# MCSPI0_CFG register map
Vendor: Texas Instruments
Peripheral module from a debugger description file (folder am65x).
Registers are 32-bit, access per field, reset 0x0 unless marked. A register's access mark holds for its fields unless they carry their own. Offsets are as the file gives them; lines under a group give offsets from that group; [hi:lo] are bit positions; {n}, {i} and the like mark numbered series; 'fields as' and 'values as' point back to an identical list; <NAME> marks a mode.

## MCSPI0_CFG
0x00 MCSPI_HL_REV ro reset 0x40301A0B — IP Revision Identifier (X.Y.R) Used by software to track features, bugs, and compatibility
  [31:0] REVISION — IP Revision
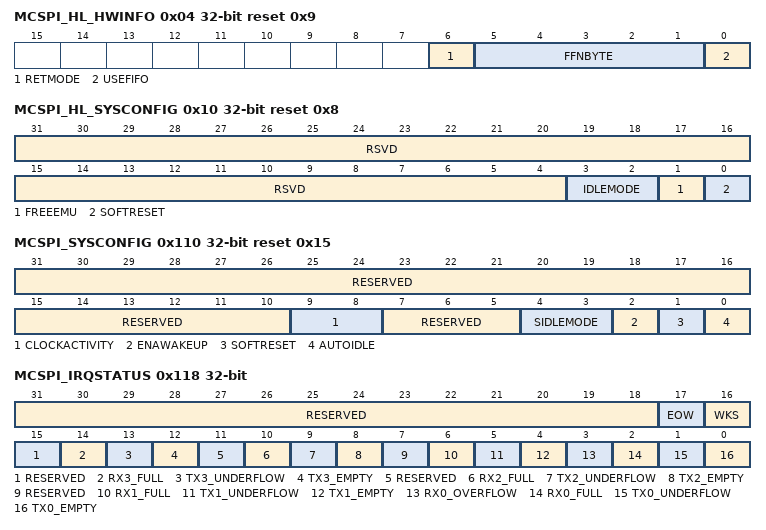
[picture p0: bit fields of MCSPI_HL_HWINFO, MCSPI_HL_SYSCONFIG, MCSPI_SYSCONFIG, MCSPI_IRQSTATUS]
0x04 MCSPI_HL_HWINFO ro reset 0x9 — Information about the IP module's hardware configuration, that is, typically the module's HDL generics (if any). Actual field format and encoding is up to the module's designer to decide. Some of the MCSPI features described in this section may not be supported on this family of devices. For more information, see , MCSPI Not Supported Features.
  [6] RETMODE — Retention Mode generic parameter. This bit field indicates whether the retention mode is supported using the pin PIRFFRET.
  [5:1] FFNBYTE — FIFO number of byte generic parameter 1h (R) = FIFO 16 bytes depth 2h (R) = FIFO 32 bytes depth 4h (R) = FIFO 64 bytes depth 8h (R) = FIFO 128 bytes depth 10h (R) = FIFO 256 bytes depth
  [0] USEFIFO — Use of a FIFO enable: 0h (R) = FIFO not implemented in design 1h (R) = FIFO and its management implemented in design with depth defined by FFNBYTE generic
0x10 MCSPI_HL_SYSCONFIG reset 0x8 — Clock management configuration Some of the MCSPI features described in this section may not be supported on this family of devices. For more information, see , MCSPI Not Supported Features.
  [31:4] RSVD ro — Reads returns 0
  [3:2] IDLEMODE rw — Configuration of the local target state management mode. 0h (R/W) = Force-idle mode: local target's IDLE state follows (acknowledges) the system's clock stop requests unconditionally, that is, regardless of the IP module's internal requirements. Backup mode, for debug only. 1h (R/W) = No-idle mode: local target never enters IDLE state. Backup mode, for debug only. 2h (R/W) = Smart-idle mode: local target's IDLE state eventually follows (acknowledges) the system's clock stop requests, depending on the IP module's internal requirements. IP module shall not generate (IRQ- or DMA-request-related) wake-up events. 3h (R/W) = Smart-idle wake-up-capable mode: local target's IDLE state eventually follows (acknowledges) the system's clock stop requests, depending on the IP module's internal requirements. IP module may generate (IRQ- or DMA-request-related) wake-up events when in IDLE state.
  [1] FREEEMU rw — Sensitivity to emulation (debug) suspend input signal. 0h (R/W) = IP module is sensitive to emulation suspend. 1h (R/W) = IP module is not sensitive to emulation suspend.
  [0] SOFTRESET rw — Software reset. (Optional) 0h (R/W) = Reset done, no pending action 1h (R/W) = Initiate software reset
0x100 MCSPI_REVISION ro reset 0x2B — This register contains the revision number.
  [31:0] REVISION — IP revision
0x110 MCSPI_SYSCONFIG reset 0x15 — This register allows controlling various parameters of the configuration interface and is not affected by software reset. Some of the MCSPI features described in this section may not be supported on this family of devices. For more information, see , MCSPI Not Supported Features.
  [31:10] RESERVED ro — Reads returns 0
  [9:8] CLOCKACTIVITY rw — Clocks activity during wake-up mode period 0h (R/W) = Interface and functional clocks may be switched off. 1h (R/W) = Interface clock is maintained. Functional clock may be switched off. 2h (R/W) = Functional clock is maintained. Interface clock may be switched off. 3h (R/W) = Interface and functional clocks are maintained.
  [7:5] RESERVED ro — Reads returns 0
  [4:3] SIDLEMODE rw — Power management 0h (R/W) = If an IDLE request is detected, the MCSPI acknowledges it unconditionally and goes in inactive mode. Interrupt, DMA requests and wake-up lines are unconditionally deasserted and the module wake-up capability is deactivated even if the 1h (R/W) = If an IDLE request is detected, the request is ignored and the module does not switch to wake-up mode, and keeps on behaving normally. 2h (R/W) = If an IDLE request is detected, the module will switch to wake-up mode based on its internal activity, and the wake-up capability can be used if the bit 3h (R/W) = Reserved - do not use.
  [2] ENAWAKEUP rw — Wake-up feature control 0h (R/W) = Wake-up capability is disabled. 1h (R/W) = Wake-up capability is enabled.
  [1] SOFTRESET rw — Software reset. During reads it always returns 0. 0h (R/W) = (write) Normal mode 1h (R/W) = (write) Set this bit to 1 to trigger a module reset. The bit is automatically reset by the hardware.
  [0] AUTOIDLE rw — Internal interface clock-gating strategy 0h (R/W) = Interface clock is free-running. 1h (R/W) = Automatic interface clock gating strategy is applied, based on the configuration interface activity.
0x114 MCSPI_SYSSTATUS ro reset 0x1 — This register provides status information about the module excluding the interrupt status information.
  [0] RESETDONE — Internal reset monitoring 0h (R) = Internal module reset is ongoing 1h (R) = Reset completed
0x118 MCSPI_IRQSTATUS access not given — The interrupt status regroups all the status of the module internal events that can generate an interrupt. Some of the MCSPI features described in this section may not be supported on this family of devices. For more information, see , MCSPI Not Supported Features.
  [31:18] RESERVED ro — Reads returns 0
  [17] EOW — End of word count event when a channel is enabled using the FIFO buffer and the channel had sent the number of MCSPI word defined by 0h (R/W) = Event false 1h (R/W) = Event status bit is reset (access RW1C)
  [16] WKS — Wake-up event in slave mode when an active control signal is detected on the SPIEN line programmed in the field 0h (R/W) = Event status bit unchanged 1h (R/W) = Event is pending (access RW1C)
  [15] RESERVED ro — Reads returns 0
  [14] RX3_FULL — Receiver register is full or almost full. Only when Channel 3 is enabled 0h (R/W) = Event status bit unchanged 1h (R/W) = Event is pending (access RW1C)
  [13] TX3_UNDERFLOW — Transmitter register underflow. Only when Channel 3 is enabled. 0h (R/W) = Event status bit unchanged 1h (R/W) = Event is pending (access RW1C)
  [12] TX3_EMPTY — Transmitter register is empty or almost empty. 0h (R/W) = Event status bit unchanged 1h (R/W) = Event is pending (access RW1C)
  [11] RESERVED ro — Reads returns 0.
  [10] RX2_FULL — Receiver register full or almost full. Channel 2 0h (R/W) = Event status bit unchanged 1h (R/W) = Event is pending (access RW1C)
  [9] TX2_UNDERFLOW — Transmitter register underflow. Channel 2 0h (R/W) = Event status bit unchanged 1h (R/W) = Event is pending (access RW1C)
  [8] TX2_EMPTY — Transmitter register empty or almost empty. Channel 2 0h (R/W) = Event status bit unchanged 1h (R/W) = Event is pending (access RW1C)
  [7] RESERVED ro — Reads returns 0
  [6] RX1_FULL — Receiver register full or almost full. Channel 1 0h (R/W) = Event status bit unchanged 1h (R/W) = Event is pending (access RW1C)
  [5] TX1_UNDERFLOW — Transmitter register underflow. Channel 1 0h (R/W) = Event status bit unchanged 1h (R/W) = Event is pending (access RW1C)
  [4] TX1_EMPTY — Transmitter register empty or almost empty. Channel 1 0h (R/W) = Event status bit unchanged 1h (R/W) = Event is pending (access RW1C)
  [3] RX0_OVERFLOW — Receiver register overflow (slave mode only). Channel 0 0h (R/W) = Event status bit unchanged 1h (R/W) = Event is pending (access RW1C)
  [2] RX0_FULL — Receiver register full or almost full. Channel 0 0h (R/W) = Event status bit unchanged 1h (R/W) = Event is pending (access RW1C)
  [1] TX0_UNDERFLOW — Transmitter register underflow. Channel 0 0h (R/W) = Event status bit unchanged 1h (R/W) = Event is pending (access RW1C)
  [0] TX0_EMPTY — Transmitter register empty or almost empty. Channel 0 0h (R/W) = Event status bit unchanged 1h (R/W) = Event is pending (access RW1C)
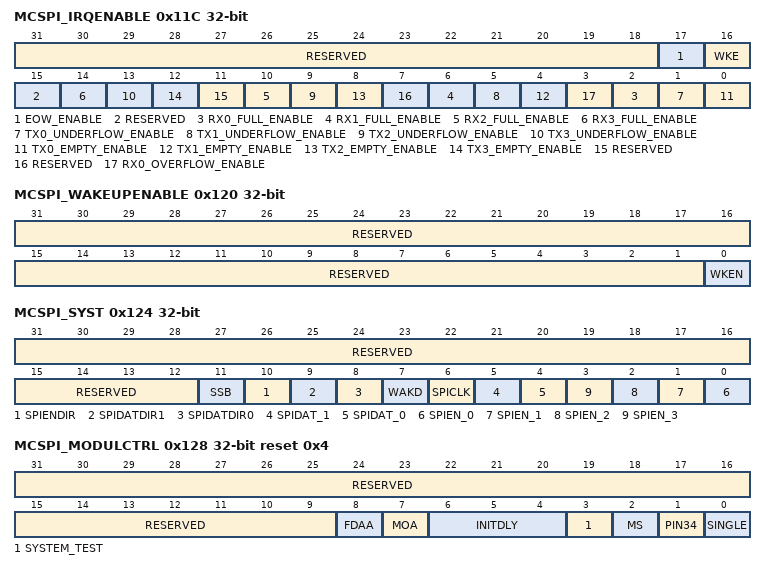
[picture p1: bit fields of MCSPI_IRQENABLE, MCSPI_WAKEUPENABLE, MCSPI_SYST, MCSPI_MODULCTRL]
0x11C MCSPI_IRQENABLE — This register allows enabling/disabling of the module internal sources of interrupt, on an event-by-event basis. Some of the MCSPI features described in this section may not be supported on this family of devices. For more information, see , MCSPI Not Supported Features.
  [31:18] RESERVED ro — Reads return 0.
  [17] EOW_ENABLE rw — End of Word count Interrupt Enable. 0h (R/W) = Interrupt disabled 1h (R/W) = Interrupt enabled
  [16] WKE rw — Wake-up event interrupt enable in slave mode when an active control signal is detected on the SPIEN line programmed in the 0h (R/W) = Interrupt disabled 1h (R/W) = Interrupt enabled
  [15] RESERVED ro — Reads returns 0.
  [4n+2] RX{n}_FULL_ENABLE rw (n=0..3) — Receiver register Full Interrupt Enable. Channel {n} 0h (R/W) = Interrupt disabled 1h (R/W) = Interrupt enabled
  [4n+1] TX{n}_UNDERFLOW_ENABLE rw (n=0..3) — Transmitter register Underflow Interrupt Enable. Channel {n} 0h (R/W) = Interrupt disabled 1h (R/W) = Interrupt enabled
  [4n] TX{n}_EMPTY_ENABLE rw (n=0..3) — Transmitter register Empty Interrupt Enable. Channel {n} 0h (R/W) = Interrupt disabled 1h (R/W) = Interrupt enabled
  [11] RESERVED ro — Reads return 0.
  [7] RESERVED ro — Reads return 0.
  [3] RX0_OVERFLOW_ENABLE rw — Receiver register Overflow Interrupt Enable. Channel 0 0h (R/W) = Interrupt disabled 1h (R/W) = Interrupt enabled
0x120 MCSPI_WAKEUPENABLE — The wake-up enable register allows enabling and disabling of the module internal sources of wakeup on event-by-event basis. Some of the MCSPI features described in this section may not be supported on this family of devices. For more information, see , MCSPI Not Supported Features.
  [31:1] RESERVED ro — Reads returns 0.
  [0] WKEN rw — Wake-up functionality in slave mode when an active control signal is detected on the SPIEN line programmed in the 0h (R/W) = The event is not allowed to wake-up the system, even if the global control bit 1h (R/W) = The event is allowed to wake-up the system if the global control bit
0x124 MCSPI_SYST — This register is used to check the correctness of the system interconnect either internally to peripheral bus, or externally to device I/O pads, when the module is configured in system test (SYSTEST) mode.
  [31:12] RESERVED ro — Reads returns 0.
  [11] SSB rw — Set status bit 0h (R/W) = No action. Writing 0 does not clear already set status bits. This bit must be cleared before trying to clear a status bit of the 1h (R/W) = Force to 1 all status bits of
  [10] SPIENDIR rw — Set the direction of the SPIEN[3:0] lines and SPICLK line. 0h (R/W) = Output (as in master mode) 1h (R/W) = Input (as in slave mode)
  [9] SPIDATDIR1 rw — Set the direction of the SPIDAT[1]. 0h (R/W) = Output 1h (R/W) = Input
  [8] SPIDATDIR0 rw — Set the direction of the SPIDAT[0]. 0h (R/W) = Output 1h (R/W) = Input
  [7] WAKD rw — SWAKEUP output (signal data value of internal signal to system). 0h (R/W) = The pin is driven low. 1h (R/W) = The pin is driven high.
  [6] SPICLK rw — SPICLK line (signal data value)
  [5] SPIDAT_1 rw — SPIDAT[1] line (signal data value)
  [4] SPIDAT_0 rw — SPIDAT[0] line (signal data value)
  [n] SPIEN_{n} rw (n=0..3) — SPIEN[{n}] line (signal data value)
0x128 MCSPI_MODULCTRL reset 0x4 — This register is dedicated to the configuration of the serial peripheral interface.
  [31:9] RESERVED ro — Reads returns 0.
  [8] FDAA rw — FIFO DMA address 256-bit aligned 0h (R/W) = FIFO data managed by MCSPI_TX(i) and MCSPI_RX(i) registers. 1h (R/W) = FIFO data managed by
  [7] MOA rw — Multiple word configuration interface access: 0h (R/W) = Multiple word access disabled 1h (R/W) = Multiple word access enabled with FIFO
  [6:4] INITDLY rw — Initial MCSPI delay for first transfer: 0h (R/W) = No delay for first MCSPI transfer. 1h (R/W) = The controller wait 4 MCSPI bus clock 2h (R/W) = The controller wait 8 MCSPI bus clock 3h (R/W) = The controller wait 16 MCSPI bus clock 4h (R/W) = The controller wait 32 MCSPI bus clock
  [3] SYSTEM_TEST rw — Enables the system test mode 0h (R/W) = Functional mode 1h (R/W) = System test mode (SYSTEST)
  [2] MS rw — Master/slave 0h (R/W) = Master - The module generates the SPICLK and SPIEN[3:0]. 1h (R/W) = Slave - The module receives the SPICLK and SPIEN[3:0].
  [1] PIN34 rw — Pin mode selection: 0h (R/W) = SPIEN is used as a chip-select. 1h (R/W) = SPIEN is not used. In this mode all related options to chip-select have no meaning.
  [0] SINGLE rw — Single channel/Multi Channel (master mode only) 0h (R/W) = More than one channel will be used in master mode. 1h (R/W) = Only one channel will be used in master mode. This bit must be set in Force SPIEN[i] mode.
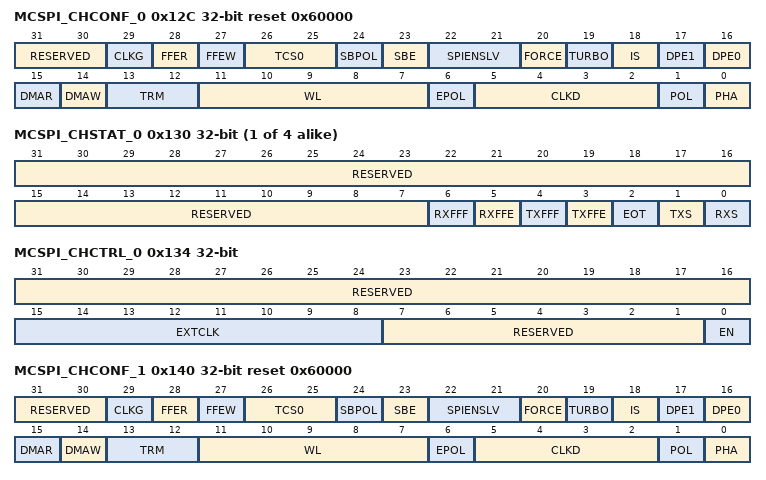
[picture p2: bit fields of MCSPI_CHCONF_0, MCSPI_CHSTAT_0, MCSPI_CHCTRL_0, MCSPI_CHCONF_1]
0x12C MCSPI_CHCONF_0 reset 0x60000 — This register is dedicated to the configuration of the channel i.
  [31:30] RESERVED ro — Read returns 0.
  [29] CLKG rw — Clock divider granularity 0h (R/W) = Clock granularity of power of 2 1h (R/W) = One clock cycle granularity
  [28] FFER rw — FIFO enabled for receive: Only one channel can have this bit field set. 0h (R/W) = The buffer is not used to receive data. 1h (R/W) = The buffer is used to receive data.
  [27] FFEW rw — FIFO enabled for transmit: Only one channel can have this bit field set. 0h (R/W) = The buffer is not used to transmit data. 1h (R/W) = The buffer is used to transmit data.
  [26:25] TCS0 rw — Chip-select time control 0h (R/W) = 0.5 clock cycle 1h (R/W) = 1.5 clock cycles 2h (R/W) = 2.5 clock cycles 3h (R/W) = 3.5 clock cycles
  [24] SBPOL rw — Start-bit polarity 0h (R/W) = Start-bit polarity is held to 0 during MCSPI transfer. 1h (R/W) = Start-bit polarity is held to 1 during MCSPI transfer.
  [23] SBE rw — Start-bit enable for MCSPI transfer 0h (R/W) = Default MCSPI transfer length as specified by WL bit field 1h (R/W) = Start bit D/CX added before MCSPI transfer polarity is defined by
  [22:21] SPIENSLV rw — Channel 0 only and slave mode only: MCSPI slave select signal detection. 0h (R/W) = Detection enabled only on SPIEN[0] 1h (R/W) = Detection enabled only on SPIEN[1] 2h (R/W) = Detection enabled only on SPIEN[2] 3h (R/W) = Detection enabled only on SPIEN[3]
  [20] FORCE rw — Manual SPIEN assertion to keep SPIEN active between MCSPI words (single channel master mode only). 0h (R/W) = Writing 0 into this bit drives low the SPIEN line when 1h (R/W) = Writing 1 into this bit drives high the SPIEN line when
  [19] TURBO rw — Turbo mode 0h (R/W) = Turbo is deactivated (recommended for single MCSPI word transfer). 1h (R/W) = Turbo is activated to maximize the throughput for multiple MCSPI words transfer.
  [18] IS rw — Input Select 0h (R/W) = Data line 0 (SPIDAT[0]) selected for reception 1h (R/W) = Data line 1 (SPIDAT[1]) selected for reception
  [17] DPE1 rw — Transmission enable for data line 1 0h (R/W) = Data line 1 (SPIDAT[1]) selected for transmission 1h (R/W) = No transmission on Data Line1 (SPIDAT[1])
  [16] DPE0 rw — Transmission Enable for data line 0 0h (R/W) = Data Line0 (SPIDAT[0]) selected for transmission 1h (R/W) = No transmission on data line 0 (SPIDAT[0])
  [15] DMAR rw — DMA read request 0h (R/W) = DMA read request disabled 1h (R/W) = DMA read request enabled
  [14] DMAW rw — DMA write request. 0h (R/W) = DMA write request disabled 1h (R/W) = DMA write request enabled
  [13:12] TRM rw — Transmit/receive modes 0h (R/W) = Transmit-and-receive mode 1h (R/W) = Receive-only mode 2h (R/W) = Transmit-only mode 3h (R/W) = Reserved
  [11:7] WL rw — SPI word length 0h (R/W) = Reserved 1h (R/W) = Reserved 2h (R/W) = Reserved 3h (R/W) = The MCSPI word is 4 bits long 4h (R/W) = The MCSPI word is 5 bits long 5h (R/W) = The MCSPI word is 6 bits long 6h (R/W) = The MCSPI word is 7 bits long 7h (R/W) = The MCSPI word is 8 bits long 8h (R/W) = The MCSPI word is 9 bits long 9h (R/W) = The MCSPI word is 10 bits long Ah (R/W) = The MCSPI word is 11 bits long Bh (R/W) = The MCSPI word is 12 bits long Ch (R/W) = The MCSPI word is 13 bits long Dh (R/W) = The MCSPI word is 14 bits long Eh (R/W) = The MCSPI word is 15 bits long Fh (R/W) = The MCSPI word is 16 bits long 10h (R/W) = The MCSPI word is 17 bits long 11h (R/W) = The MCSPI word is 18 bits long 12h (R/W) = The MCSPI word is 19 bits long 13h (R/W) = The MCSPI word is 20 bits long 14h (R/W) = The MCSPI word is 21 bits long 15h (R/W) = The MCSPI word is 22 bits long 16h (R/W) = The MCSPI word is 23 bits long 17h (R/W) = The MCSPI word is 24 bits long 18h (R/W) = The MCSPI word is 25 bits long 19h (R/W) = The MCSPI word is 26 bits long 1Ah (R/W) = The MCSPI word is 27 bits long 1Bh (R/W) = The MCSPI word is 28 bits long 1Ch (R/W) = The MCSPI word is 29 bits long 1Dh (R/W) = The MCSPI word is 30 bits long 1Eh (R/W) = The MCSPI word is 31 bits long 1Fh (R/W) = The MCSPI word is 32 bits long
  [6] EPOL rw — SPIEN polarity 0h (R/W) = SPIEN is held high during the ACTIVE state. 1h (R/W) = SPIEN is held low during the ACTIVE state.
  [5:2] CLKD rw — Frequency divider for SPICLK (only when the module is a Master MCSPI device). A programmable clock divider divides the MCSPI reference clock (SPICLKREF) with a 4-bit value, and results in a new clock SPICLK available to shift-in and shift-out data. By default the clock divider ratio has a power of 2 granularity when 0h (R/W) = 1 1h (R/W) = 2 2h (R/W) = 4 3h (R/W) = 8 4h (R/W) = 16 5h (R/W) = 32 6h (R/W) = 64 7h (R/W) = 128 8h (R/W) = 256 9h (R/W) = 512 Ah (R/W) = 1024 Bh (R/W) = 2048 Ch (R/W) = 4096 Dh (R/W) = 8192 Eh (R/W) = 16384 Fh (R/W) = 32768
  [1] POL rw — SPICLK polarity (see 0h (R/W) = SPICLK is held low during the INACTIVE state 1h (R/W) = SPICLK is held high during the INACTIVE state
  [0] PHA rw — SPICLK phase (see 0h (R/W) = Data are latched on odd-numbered edges of SPICLK. 1h (R/W) = Data are latched on even-numbered edges of SPICLK.
{0x130+0x14*i} MCSPI_CHSTAT_{i} ro (i=0..3) — This register provides status information about transmitter and receiver registers of channel i.
  [31:7] RESERVED — Read returns 0.
  [6] RXFFF — Channel i FIFO receive buffer full status 0h (R) = FIFO receive buffer is not full 1h (R) = FIFO receive buffer is full
  [5] RXFFE — Channel i FIFO receive buffer empty status 0h (R) = FIFO receive buffer is not empty 1h (R) = FIFO receive buffer is empty
  [4] TXFFF — Channel i FIFO transmit buffer full status 0h (R) = FIFO transmit buffer is not full 1h (R) = FIFO transmit buffer is full
  [3] TXFFE — Channel i FIFO transmit buffer empty status 0h (R) = FIFO transmit buffer is not empty 1h (R) = FIFO transmit buffer is empty
  [2] EOT — Channel i end of transfer status. The definitions of beginning and end of transfer vary with master versus slave and the transfer format (transmit/receive modes, turbo mode). See dedicated chapters for details. 0h (R) = This flag is automatically cleared when the shift register is loaded with the data from the transmitter register (beginning of transfer). 1h (R) = This flag is automatically set to one at the end of an MCSPI transfer.
  [1] TXS — Channel i transmitter register status 0h (R) = Register is full. 1h (R) = Register is empty.
  [0] RXS — Channel i receiver register status 0h (R) = Register is empty. 1h (R) = Register is full.
0x134 MCSPI_CHCTRL_0 — This register is dedicated to enable channel i.
  [31:16] RESERVED ro — Read returns 0.
  [15:8] EXTCLK rw — Clock ratio extension: 0h (R/W) = Clock ratio is CLKD + 1. 1h (R/W) = Clock ratio is CLKD + 1 + 16. FFh (R/W) = Clock ratio is CLKD + 1 + 4080.
  [7:1] RESERVED ro — Read returns 0.
  [0] EN rw — Channel enable 0h (R/W) = Channel i is not active. 1h (R/W) = Channel i is active.
0x138 MCSPI_TX_0 rw — This register contains a single MCSPI word for channel ito transmit on the serial link, whatever MCSPI word length is.
  [31:0] TDATA — Channel i data to transmit
{0x13C+0x14*i} MCSPI_RX_{i} ro (i=0..3) — This register contains a single MCSPI word for channel i received through the serial link, whatever MCSPI word length is.
  [31:0] RDATA — Channel i received data
0x140 MCSPI_CHCONF_1 reset 0x60000 — This register is dedicated to the configuration of the channel i.
  fields as MCSPI_CHCONF_0
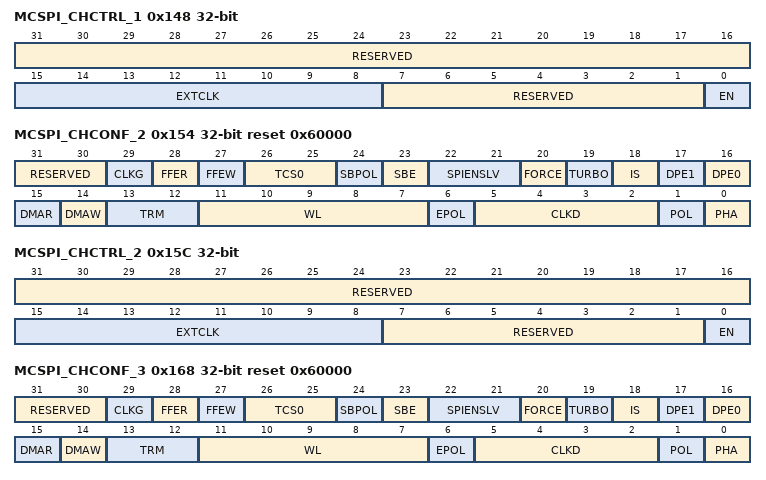
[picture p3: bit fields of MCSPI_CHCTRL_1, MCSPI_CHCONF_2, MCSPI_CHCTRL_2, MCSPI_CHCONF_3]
0x148 MCSPI_CHCTRL_1 — This register is dedicated to enable channel i.
  [31:16] RESERVED ro — Read returns 0.
  [15:8] EXTCLK rw — Clock ratio extension: 0h (R/W) = Clock ratio is CLKD + 1. 1h (R/W) = Clock ratio is CLKD + 1 + 16. FFh (R/W) = Clock ratio is CLKD + 1 + 4080.
  [7:1] RESERVED ro — Read returns 0.
  [0] EN rw — Channel enable 0h (R/W) = Channel 'i' is not active. 1h (R/W) = Channel 'i' is active.
{0x138+0x14*i} MCSPI_TX_{i} rw (i=1..3) — This register contains a single MCSPI word for channel i to transmit on the serial link, whatever MCSPI word length is.
  [31:0] TDATA — Channel i data to transmit
0x154 MCSPI_CHCONF_2 reset 0x60000 — This register is dedicated to the configuration of the channel i
  fields as MCSPI_CHCONF_0
0x15C MCSPI_CHCTRL_2 — This register is dedicated to enable channel i.
  fields as MCSPI_CHCTRL_0
0x168 MCSPI_CHCONF_3 reset 0x60000 — This register is dedicated to the configuration of the channel i
  fields as MCSPI_CHCONF_0
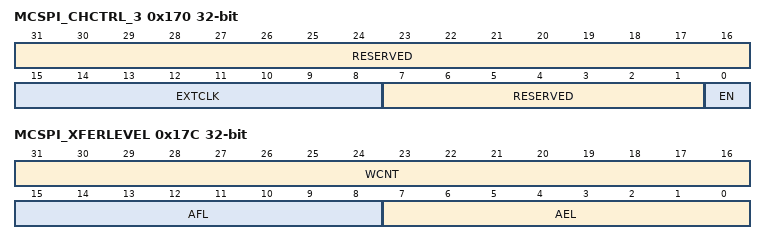
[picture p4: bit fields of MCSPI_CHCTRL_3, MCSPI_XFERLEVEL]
0x170 MCSPI_CHCTRL_3 — This register is dedicated to enable channel i.
  fields as MCSPI_CHCTRL_1
0x17C MCSPI_XFERLEVEL rw — This register provides transfer levels needed while using FIFO buffer during transfer.
  [31:16] WCNT — SPI word counter. 0h (R/W) = Counter not used 1h (R/W) = One word FFFEh (R/W) = 65534 MCSPI word FFFFh (R/W) = 65535 MCSPI word
  [15:8] AFL — Buffer almost full 0h (R/W) = 1 byte 1h (R/W) = 2 bytes FEh (R/W) = 255bytes FFh (R/W) = 256bytes
  [7:0] AEL — Buffer almost empty. 0h (R/W) = 1 byte 1h (R/W) = 2 bytes FEh (R/W) = 255 bytes FFh (R/W) = 256bytes
0x180 MCSPI_DAFTX rw — This register contains the MCSPI words to be transmitted on the MCSPI bus when FIFO is used and DMA address is aligned on 256 bit. This register is an image of one of the MCSPI_TX registers corresponding to the channel which has its FIFO enabled.
  [31:0] DAFTDATA — FIFO data to transmit with DMA 256 bit aligned address. This field is only used when
0x1A0 MCSPI_DAFRX ro — This register contains the MCSPI words received from the MCSPI bus when FIFO is used and DMA address is aligned on 256 bit. This register is an image of one of the MCSPI_RX registers corresponding to the channel which has its FIFO enabled.
  [31:0] DAFRDATA — FIFO data received with DMA 256 bit aligned address. This field is only used when
